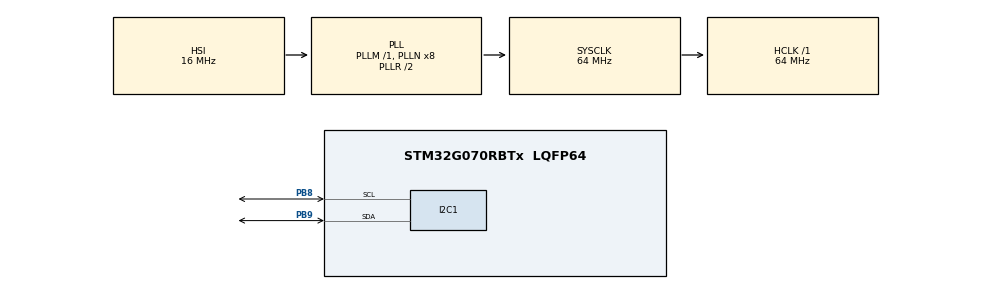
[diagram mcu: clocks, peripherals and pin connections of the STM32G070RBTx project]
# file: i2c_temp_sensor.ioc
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I2C1.Timing=0x10707DBC
Mcu.Family=STM32G0
Mcu.Name=STM32G070RBTx
Mcu.Package=LQFP64
PB8.Mode=I2C
PB8.Signal=I2C1_SCL
PB9.Mode=I2C
PB9.Signal=I2C1_SDA
PC13.Mode=SYS_WakeUp1
PC13.Signal=SYS_WKUP2
PC14-OSC32_IN\ (PC14).Mode=LSE-External-Oscillator
PC14-OSC32_IN\ (PC14).Signal=RCC_OSC32_IN
PC15-OSC32_OUT\ (PC15).Mode=LSE-External-Oscillator
PC15-OSC32_OUT\ (PC15).Signal=RCC_OSC32_OUT
PF0-OSC_IN\ (PF0).GPIO_Label=MCO
PF0-OSC_IN\ (PF0).Mode=HSE-External-Clock-Source
PF0-OSC_IN\ (PF0).Signal=RCC_OSC_IN
ProjectManager.HeapSize=0x200
ProjectManager.StackSize=0x400
ProjectManager.TargetToolchain=STM32CubeIDE
RCC.ADCFreq_Value=64000000
RCC.AHBFreq_Value=64000000
RCC.CortexFreq_Value=64000000
RCC.EXTERNAL_CLOCK_VALUE=12288000
RCC.HCLKFreq_Value=64000000
RCC.HSE_VALUE=8000000
RCC.HSI_VALUE=16000000
RCC.SYSCLKFreq_VALUE=64000000
RCC.SYSCLKSource=RCC_SYSCLKSOURCE_PLLCLK
RCC.VCOOutputFreq_Value=128000000
VP_SYS_VS_DBSignals.Mode=DisableDeadBatterySignals
board=NUCLEO-G070RB

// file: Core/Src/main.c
/* USER CODE BEGIN Header */
/**
  ******************************************************************************
  * @file           : main.c
  * @brief          : Main program body
  ******************************************************************************
  * @attention
  *
  * Copyright (c) 2024 STMicroelectronics.
  * All rights reserved.
  *
  * This software is licensed under terms that can be found in the LICENSE file
  * in the root directory of this software component.
  * If no LICENSE file comes with this software, it is provided AS-IS.
  *
  ******************************************************************************
  */
/* USER CODE END Header */
#include "main.h"

/* USER CODE BEGIN Includes */
#include "bmp180_for_stm32_hal.h"
#include "stdio.h"
#include "stdlib.h"
#include "string.h"

/* USER CODE END Includes */

I2C_HandleTypeDef hi2c1;

void SystemClock_Config(void);
static void MX_GPIO_Init(void);
static void MX_I2C1_Init(void);

int main(void)
{

  /* USER CODE BEGIN 1 */
uint8_t buf[12];
  /* USER CODE END 1 */

  /* MCU Configuration--------------------------------------------------------*/

  /* Reset of all peripherals, Initializes the Flash interface and the Systick. */
  HAL_Init();

  /* Configure the system clock */
  SystemClock_Config();

  /* Initialize all configured peripherals */
  MX_GPIO_Init();
  MX_I2C1_Init();

  /* Infinite loop */
  while (1)
  {

    /* USER CODE BEGIN 3 */
    /* Reads temperature. */
		int8_t temperature = BMP180_GetRawTemperature();
    HAL_I2C_Slave_Transmit(&hi2c1,(uint8_t *)temperature,1,1000);
    HAL_Delay(100);
  }
  /* USER CODE END 3 */
}

void SystemClock_Config(void)
{
  RCC_OscInitTypeDef RCC_OscInitStruct = {0};
  RCC_ClkInitTypeDef RCC_ClkInitStruct = {0};

  /** Configure the main internal regulator output voltage
  */
  HAL_PWREx_ControlVoltageScaling(PWR_REGULATOR_VOLTAGE_SCALE1);

  /** Initializes the RCC Oscillators according to the specified parameters
  * in the RCC_OscInitTypeDef structure.
  */
  RCC_OscInitStruct.OscillatorType = RCC_OSCILLATORTYPE_HSI;
  RCC_OscInitStruct.HSIState = RCC_HSI_ON;
  RCC_OscInitStruct.HSIDiv = RCC_HSI_DIV1;
  RCC_OscInitStruct.HSICalibrationValue = RCC_HSICALIBRATION_DEFAULT;
  RCC_OscInitStruct.PLL.PLLState = RCC_PLL_ON;
  RCC_OscInitStruct.PLL.PLLSource = RCC_PLLSOURCE_HSI;
  RCC_OscInitStruct.PLL.PLLM = RCC_PLLM_DIV1;
  RCC_OscInitStruct.PLL.PLLN = 8;
  RCC_OscInitStruct.PLL.PLLP = RCC_PLLP_DIV2;
  RCC_OscInitStruct.PLL.PLLR = RCC_PLLR_DIV2;
  if (HAL_RCC_OscConfig(&RCC_OscInitStruct) != HAL_OK)
  {
    Error_Handler();
  }

  /** Initializes the CPU, AHB and APB buses clocks
  */
  RCC_ClkInitStruct.ClockType = RCC_CLOCKTYPE_HCLK|RCC_CLOCKTYPE_SYSCLK
                              |RCC_CLOCKTYPE_PCLK1;
  RCC_ClkInitStruct.SYSCLKSource = RCC_SYSCLKSOURCE_PLLCLK;
  RCC_ClkInitStruct.AHBCLKDivider = RCC_SYSCLK_DIV1;
  RCC_ClkInitStruct.APB1CLKDivider = RCC_HCLK_DIV1;

  if (HAL_RCC_ClockConfig(&RCC_ClkInitStruct, FLASH_LATENCY_2) != HAL_OK)
  {
    Error_Handler();
  }
}

static void MX_I2C1_Init(void)
{

  hi2c1.Instance = I2C1;
  hi2c1.Init.Timing = 0x10707DBC;
  hi2c1.Init.OwnAddress1 = 0;
  hi2c1.Init.AddressingMode = I2C_ADDRESSINGMODE_7BIT;
  hi2c1.Init.DualAddressMode = I2C_DUALADDRESS_DISABLE;
  hi2c1.Init.OwnAddress2 = 0;
  hi2c1.Init.OwnAddress2Masks = I2C_OA2_NOMASK;
  hi2c1.Init.GeneralCallMode = I2C_GENERALCALL_DISABLE;
  hi2c1.Init.NoStretchMode = I2C_NOSTRETCH_DISABLE;
  if (HAL_I2C_Init(&hi2c1) != HAL_OK)
  {
    Error_Handler();
  }

  /** Configure Analogue filter
  */
  if (HAL_I2CEx_ConfigAnalogFilter(&hi2c1, I2C_ANALOGFILTER_ENABLE) != HAL_OK)
  {
    Error_Handler();
  }

  /** Configure Digital filter
  */
  if (HAL_I2CEx_ConfigDigitalFilter(&hi2c1, 0) != HAL_OK)
  {
    Error_Handler();
  }

}

static void MX_GPIO_Init(void)
{

  /* GPIO Ports Clock Enable */
  __HAL_RCC_GPIOC_CLK_ENABLE();
  __HAL_RCC_GPIOF_CLK_ENABLE();
  __HAL_RCC_GPIOB_CLK_ENABLE();

}

void Error_Handler(void)
{
  __disable_irq();
  while (1)
  {
  }
}
